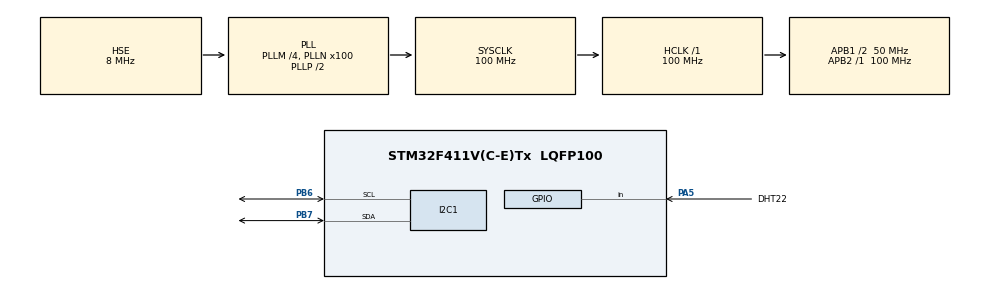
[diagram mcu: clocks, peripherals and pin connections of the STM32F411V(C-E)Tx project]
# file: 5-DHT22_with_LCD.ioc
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Mcu.Family=STM32F4
Mcu.Name=STM32F411V(C-E)Tx
Mcu.Package=LQFP100
NVIC.PriorityGroup=NVIC_PRIORITYGROUP_4
NVIC.TIM2_IRQn=true\:0\:0\:false\:false\:true\:true\:true\:true
PA13.Mode=Serial_Wire
PA13.Signal=SYS_JTMS-SWDIO
PA14.Mode=Serial_Wire
PA14.Signal=SYS_JTCK-SWCLK
PA5.GPIO_Label=DHT22
PA5.GPIO_PuPd=GPIO_NOPULL
PA5.Signal=GPIO_Input
PB6.Mode=I2C
PB6.Signal=I2C1_SCL
PB7.Mode=I2C
PB7.Signal=I2C1_SDA
PH0\ -\ OSC_IN.Mode=HSE-External-Oscillator
PH0\ -\ OSC_IN.Signal=RCC_OSC_IN
PH1\ -\ OSC_OUT.Mode=HSE-External-Oscillator
PH1\ -\ OSC_OUT.Signal=RCC_OSC_OUT
ProjectManager.HeapSize=0x200
ProjectManager.StackSize=0x400
ProjectManager.TargetToolchain=STM32CubeIDE
RCC.48MHZClocksFreq_Value=50000000
RCC.AHBFreq_Value=100000000
RCC.APB1CLKDivider=RCC_HCLK_DIV2
RCC.APB1Freq_Value=50000000
RCC.APB1TimFreq_Value=100000000
RCC.APB2Freq_Value=100000000
RCC.APB2TimFreq_Value=100000000
RCC.CortexFreq_Value=100000000
RCC.HCLKFreq_Value=100000000
RCC.HSE_VALUE=8000000
RCC.HSI_VALUE=16000000
RCC.LSE_VALUE=32768
RCC.PLLM=4
RCC.PLLN=100
RCC.PLLSourceVirtual=RCC_PLLSOURCE_HSE
RCC.SYSCLKFreq_VALUE=100000000
RCC.SYSCLKSource=RCC_SYSCLKSOURCE_PLLCLK
RCC.VCOOutputFreq_Value=200000000
TIM2.Prescaler=99
VP_TIM2_VS_ClockSourceINT.Mode=Internal
board=custom

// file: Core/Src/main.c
/* USER CODE BEGIN Header */
/**
  ******************************************************************************
  * @file           : main.c
  * @brief          : Main program body
  ******************************************************************************
  * @attention
  *
  * Copyright (c) 2025 STMicroelectronics.
  * All rights reserved.
  *
  * This software is licensed under terms that can be found in the LICENSE file
  * in the root directory of this software component.
  * If no LICENSE file comes with this software, it is provided AS-IS.
  *
  ******************************************************************************
  */
/* USER CODE END Header */
#include "main.h"

/* USER CODE BEGIN Includes */
#include "i2c_lcd.h"  // Thư viện LCD
#include "dhtxx.h"    // Thư viện DHT
#include <stdio.h>
#include <dwt.h>
/* USER CODE END Includes */

I2C_HandleTypeDef hi2c1;

TIM_HandleTypeDef htim2;

/* USER CODE BEGIN PV */
I2C_LCD_HandleTypeDef lcd; // Biến điều khiển LCD
DHTxx_Drv_t dht22;       // Biến điều khiển DHT22

char temp_str[16];     // Chuỗi để hiển thị nhiệt độ
char hum_str[16];      // Chuỗi để hiển thị độ ẩm
/* USER CODE END PV */

void SystemClock_Config(void);
static void MX_GPIO_Init(void);
static void MX_I2C1_Init(void);
static void MX_TIM2_Init(void);

int main(void)
{

  /* MCU Configuration--------------------------------------------------------*/

  /* Reset of all peripherals, Initializes the Flash interface and the Systick. */
  HAL_Init();

  /* Configure the system clock */
  SystemClock_Config();

  /* Initialize all configured peripherals */
  MX_GPIO_Init();
  MX_I2C1_Init();
  MX_TIM2_Init();
  /* USER CODE BEGIN 2 */
  DwtInit();
  // --- Khởi tạo LCD ---
    lcd.hi2c = &hi2c1;
    lcd.address = 0x4E; // Địa chỉ I2C của LCD (0x27 << 1)
    lcd_init(&lcd);

    lcd_puts(&lcd, "Dang khoi dong...");
    HAL_Delay(1500);
    lcd_clear(&lcd);

    // --- Khởi tạo DHT22 ---
    dht22.DataPort = DHT22_GPIO_Port; // Dùng macro CubeMX đã tạo
    dht22.DataPin = DHT22_Pin;
    dht22.Type = DHT22;
  /* USER CODE END 2 */

  /* Infinite loop */
    while (1)
      {
        /* USER CODE END WHILE */
//        // Đọc dữ liệu từ cảm biến DHT22
//        DHT_GetData(&dht22);
//
//        // Chuyển đổi giá trị số sang chuỗi để hiển thị
//        sprintf(temp_str, "Nhiet Do: %.1f C", dht22.Temperature);
//        sprintf(hum_str,  "Do Am:   %.1f %%", dht22.Humidity);
//
//        // Hiển thị lên LCD
//        lcd_gotoxy(&lcd, 0, 0); // Di chuyển con trỏ đến hàng 0, cột 0
//        lcd_puts(&lcd, temp_str); // In chuỗi nhiệt độ
//
//        lcd_gotoxy(&lcd, 0, 1); // Di chuyển con trỏ đến hàng 1, cột 0
//        lcd_puts(&lcd, hum_str);  // In chuỗi độ ẩm
//
//        HAL_Delay(2000); // Đợi 2 giây cho lần đọc tiếp theo
    	DHT_GetData(&dht22);

    	    // Kiểm tra xem việc đọc có thành công không
    	    // Nếu cả 2 giá trị vẫn là 0 sau khi đọc, tức là đã có lỗi
    	    if (dht22.Temperature == 0 && dht22.Humidity == 0)
    	    {
    	        lcd_clear(&lcd);
    	        lcd_gotoxy(&lcd, 0, 0);
    	        lcd_puts(&lcd, "Loi doc DHT22!");
    	        lcd_gotoxy(&lcd, 0, 1);
    	        lcd_puts(&lcd, "Kiem tra day noi");
    	    }
    	    else
    	    {
    	        // Chuyển đổi giá trị số sang chuỗi để hiển thị
    	        sprintf(temp_str, "Nhiet Do: %.1f C", dht22.Temperature);
    	        sprintf(hum_str,  "Do Am:   %.1f %%", dht22.Humidity);

    	        // Hiển thị lên LCD
    	        lcd_gotoxy(&lcd, 0, 0);
    	        lcd_puts(&lcd, temp_str);
    	        lcd_gotoxy(&lcd, 0, 1);
    	        lcd_puts(&lcd, hum_str);
    	    }

    	    HAL_Delay(2000);
      }
}

void SystemClock_Config(void)
{
  RCC_OscInitTypeDef RCC_OscInitStruct = {0};
  RCC_ClkInitTypeDef RCC_ClkInitStruct = {0};

  /** Configure the main internal regulator output voltage
  */
  __HAL_RCC_PWR_CLK_ENABLE();
  __HAL_PWR_VOLTAGESCALING_CONFIG(PWR_REGULATOR_VOLTAGE_SCALE1);

  /** Initializes the RCC Oscillators according to the specified parameters
  * in the RCC_OscInitTypeDef structure.
  */
  RCC_OscInitStruct.OscillatorType = RCC_OSCILLATORTYPE_HSE;
  RCC_OscInitStruct.HSEState = RCC_HSE_ON;
  RCC_OscInitStruct.PLL.PLLState = RCC_PLL_ON;
  RCC_OscInitStruct.PLL.PLLSource = RCC_PLLSOURCE_HSE;
  RCC_OscInitStruct.PLL.PLLM = 4;
  RCC_OscInitStruct.PLL.PLLN = 100;
  RCC_OscInitStruct.PLL.PLLP = RCC_PLLP_DIV2;
  RCC_OscInitStruct.PLL.PLLQ = 4;
  if (HAL_RCC_OscConfig(&RCC_OscInitStruct) != HAL_OK)
  {
    Error_Handler();
  }

  /** Initializes the CPU, AHB and APB buses clocks
  */
  RCC_ClkInitStruct.ClockType = RCC_CLOCKTYPE_HCLK|RCC_CLOCKTYPE_SYSCLK
                              |RCC_CLOCKTYPE_PCLK1|RCC_CLOCKTYPE_PCLK2;
  RCC_ClkInitStruct.SYSCLKSource = RCC_SYSCLKSOURCE_PLLCLK;
  RCC_ClkInitStruct.AHBCLKDivider = RCC_SYSCLK_DIV1;
  RCC_ClkInitStruct.APB1CLKDivider = RCC_HCLK_DIV2;
  RCC_ClkInitStruct.APB2CLKDivider = RCC_HCLK_DIV1;

  if (HAL_RCC_ClockConfig(&RCC_ClkInitStruct, FLASH_LATENCY_3) != HAL_OK)
  {
    Error_Handler();
  }
}

static void MX_I2C1_Init(void)
{

  hi2c1.Instance = I2C1;
  hi2c1.Init.ClockSpeed = 100000;
  hi2c1.Init.DutyCycle = I2C_DUTYCYCLE_2;
  hi2c1.Init.OwnAddress1 = 0;
  hi2c1.Init.AddressingMode = I2C_ADDRESSINGMODE_7BIT;
  hi2c1.Init.DualAddressMode = I2C_DUALADDRESS_DISABLE;
  hi2c1.Init.OwnAddress2 = 0;
  hi2c1.Init.GeneralCallMode = I2C_GENERALCALL_DISABLE;
  hi2c1.Init.NoStretchMode = I2C_NOSTRETCH_DISABLE;
  if (HAL_I2C_Init(&hi2c1) != HAL_OK)
  {
    Error_Handler();
  }

}

static void MX_TIM2_Init(void)
{

  TIM_ClockConfigTypeDef sClockSourceConfig = {0};
  TIM_MasterConfigTypeDef sMasterConfig = {0};

  htim2.Instance = TIM2;
  htim2.Init.Prescaler = 99;
  htim2.Init.CounterMode = TIM_COUNTERMODE_UP;
  htim2.Init.Period = 4294967295;
  htim2.Init.ClockDivision = TIM_CLOCKDIVISION_DIV1;
  htim2.Init.AutoReloadPreload = TIM_AUTORELOAD_PRELOAD_DISABLE;
  if (HAL_TIM_Base_Init(&htim2) != HAL_OK)
  {
    Error_Handler();
  }
  sClockSourceConfig.ClockSource = TIM_CLOCKSOURCE_INTERNAL;
  if (HAL_TIM_ConfigClockSource(&htim2, &sClockSourceConfig) != HAL_OK)
  {
    Error_Handler();
  }
  sMasterConfig.MasterOutputTrigger = TIM_TRGO_RESET;
  sMasterConfig.MasterSlaveMode = TIM_MASTERSLAVEMODE_DISABLE;
  if (HAL_TIMEx_MasterConfigSynchronization(&htim2, &sMasterConfig) != HAL_OK)
  {
    Error_Handler();
  }

}

static void MX_GPIO_Init(void)
{
  GPIO_InitTypeDef GPIO_InitStruct = {0};

  /* GPIO Ports Clock Enable */
  __HAL_RCC_GPIOH_CLK_ENABLE();
  __HAL_RCC_GPIOA_CLK_ENABLE();
  __HAL_RCC_GPIOB_CLK_ENABLE();

  /*Configure GPIO pin : DHT22_Pin */
  GPIO_InitStruct.Pin = DHT22_Pin;
  GPIO_InitStruct.Mode = GPIO_MODE_INPUT;
  GPIO_InitStruct.Pull = GPIO_NOPULL;
  HAL_GPIO_Init(DHT22_GPIO_Port, &GPIO_InitStruct);

}

void Error_Handler(void)
{
  __disable_irq();
  while (1)
  {
  }
}
